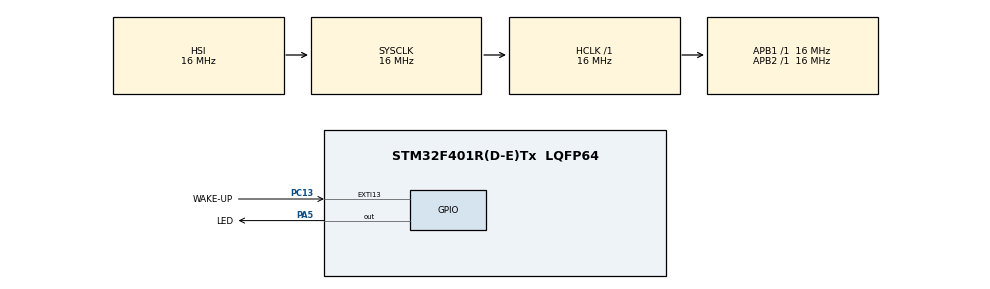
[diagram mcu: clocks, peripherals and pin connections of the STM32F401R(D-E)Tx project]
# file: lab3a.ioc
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Mcu.Family=STM32F4
Mcu.Name=STM32F401R(D-E)Tx
Mcu.Package=LQFP64
NVIC.EXTI15_10_IRQn=true\:0\:0\:false\:false\:true\:true\:true\:true
NVIC.PriorityGroup=NVIC_PRIORITYGROUP_4
PA5.GPIO_Label=LED
PA5.Signal=GPIO_Output
PC13-ANTI_TAMP.GPIO_Label=WAKE-UP
PC13-ANTI_TAMP.GPIO_ModeDefaultEXTI=GPIO_MODE_IT_FALLING
PC13-ANTI_TAMP.Signal=GPXTI13
ProjectManager.HeapSize=0x200
ProjectManager.StackSize=0x400
ProjectManager.TargetToolchain=STM32CubeIDE
RCC.AHBFreq_Value=16000000
RCC.APB1Freq_Value=16000000
RCC.APB2Freq_Value=16000000
RCC.CortexFreq_Value=16000000
RCC.HSE_VALUE=25000000
RCC.HSI_VALUE=16000000
RCC.LSE_VALUE=32768
RCC.SYSCLKFreq_VALUE=16000000
RCC.VCOOutputFreq_Value=192000000
board=custom

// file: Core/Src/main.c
/* USER CODE BEGIN Header */
/**
  ******************************************************************************
  * @file           : main.c
  * @brief          : Main program body
  ******************************************************************************
  * @attention
  *
  * Copyright (c) 2026 STMicroelectronics.
  * All rights reserved.
  *
  * This software is licensed under terms that can be found in the LICENSE file
  * in the root directory of this software component.
  * If no LICENSE file comes with this software, it is provided AS-IS.
  *
  ******************************************************************************
  */
/* USER CODE END Header */
#include "main.h"

/* ------------------------- Globals ------------------------- */
volatile uint32_t g_wakeCount = 0;
volatile uint8_t  g_doBlink  = 0;

void SystemClock_Config(void);
static void MX_GPIO_Init(void);
static void BlinkTimes(uint32_t n);

int main(void)
{

  /* MCU Configuration--------------------------------------------------------*/

  /* Reset of all peripherals, Initializes the Flash interface and the Systick. */
  HAL_Init();

  /* Configure the system clock */
  SystemClock_Config();

  /* Initialize all configured peripherals */
  MX_GPIO_Init();
  /* USER CODE BEGIN 2 */

  BlinkTimes(1);
  /* USER CODE END 2 */

  /* Infinite loop */
  while (1)
  {

	    /* If we woke due to button, perform visible action and show counter */
	    if (g_doBlink)
	    {
	      g_doBlink = 0;

	      /* Blink g_wakeCount times so you can see the counter is preserved */
	      BlinkTimes(g_wakeCount);
	    }

	    /* --- Prepare to enter STOP --- */

	    /* Clear any pending EXTI flag (prevents immediate wake / "won't sleep") */
	    __HAL_GPIO_EXTI_CLEAR_IT(GPIO_PIN_13);

	    /* (Optional) Clear WakeUp flag (safe even if not set) */
	    __HAL_PWR_CLEAR_FLAG(PWR_FLAG_WU);
	    /* Enter STOP mode (low-power regulator ON), wake on EXTI interrupt */
	    HAL_PWR_EnterSTOPMode(PWR_LOWPOWERREGULATOR_ON, PWR_STOPENTRY_WFI);

	    /* --- We resume here after wake from STOP --- */

  }
}

/* ------------------------- Blink Helper ------------------------- */
static void BlinkTimes(uint32_t n)
{
  for (uint32_t i = 0; i < n; i++)
  {
    HAL_GPIO_WritePin(GPIOA, GPIO_PIN_5, GPIO_PIN_SET);
    HAL_Delay(120);
    HAL_GPIO_WritePin(GPIOA, GPIO_PIN_5, GPIO_PIN_RESET);
    HAL_Delay(120);
  }

  /* small gap after the sequence */
  HAL_Delay(250);
}

/* ---------------------- EXTI Callback ---------------------- */
void HAL_GPIO_EXTI_Callback(uint16_t GPIO_Pin)
{
  if (GPIO_Pin == GPIO_PIN_13) /* USER button B1: PC13 */
  {
    /* Simple debounce: ignore bounces within ~150ms */
    static uint32_t lastTick = 0;
    uint32_t now = HAL_GetTick();
    if ((now - lastTick) < 150) return;
    lastTick = now;

    g_wakeCount++;
    g_doBlink = 1;
  }
}

void SystemClock_Config(void)
{
  RCC_OscInitTypeDef RCC_OscInitStruct = {0};
  RCC_ClkInitTypeDef RCC_ClkInitStruct = {0};

  /** Configure the main internal regulator output voltage
  */
  __HAL_RCC_PWR_CLK_ENABLE();
  __HAL_PWR_VOLTAGESCALING_CONFIG(PWR_REGULATOR_VOLTAGE_SCALE2);

  /** Initializes the RCC Oscillators according to the specified parameters
  * in the RCC_OscInitTypeDef structure.
  */
  RCC_OscInitStruct.OscillatorType = RCC_OSCILLATORTYPE_HSI;
  RCC_OscInitStruct.HSIState = RCC_HSI_ON;
  RCC_OscInitStruct.HSICalibrationValue = RCC_HSICALIBRATION_DEFAULT;
  RCC_OscInitStruct.PLL.PLLState = RCC_PLL_NONE;
  if (HAL_RCC_OscConfig(&RCC_OscInitStruct) != HAL_OK)
  {
    Error_Handler();
  }

  /** Initializes the CPU, AHB and APB buses clocks
  */
  RCC_ClkInitStruct.ClockType = RCC_CLOCKTYPE_HCLK|RCC_CLOCKTYPE_SYSCLK
                              |RCC_CLOCKTYPE_PCLK1|RCC_CLOCKTYPE_PCLK2;
  RCC_ClkInitStruct.SYSCLKSource = RCC_SYSCLKSOURCE_HSI;
  RCC_ClkInitStruct.AHBCLKDivider = RCC_SYSCLK_DIV1;
  RCC_ClkInitStruct.APB1CLKDivider = RCC_HCLK_DIV1;
  RCC_ClkInitStruct.APB2CLKDivider = RCC_HCLK_DIV1;

  if (HAL_RCC_ClockConfig(&RCC_ClkInitStruct, FLASH_LATENCY_0) != HAL_OK)
  {
    Error_Handler();
  }
}

static void MX_GPIO_Init(void)
{
  GPIO_InitTypeDef GPIO_InitStruct = {0};

  /* GPIO Ports Clock Enable */
  __HAL_RCC_GPIOC_CLK_ENABLE();
  __HAL_RCC_GPIOA_CLK_ENABLE();

  /*Configure GPIO pin Output Level */
  HAL_GPIO_WritePin(LED_GPIO_Port, LED_Pin, GPIO_PIN_RESET);

  /*Configure GPIO pin : WAKE_UP_Pin */
  GPIO_InitStruct.Pin = WAKE_UP_Pin;
  GPIO_InitStruct.Mode = GPIO_MODE_IT_FALLING;
  GPIO_InitStruct.Pull = GPIO_NOPULL;
  HAL_GPIO_Init(WAKE_UP_GPIO_Port, &GPIO_InitStruct);

  /*Configure GPIO pin : LED_Pin */
  GPIO_InitStruct.Pin = LED_Pin;
  GPIO_InitStruct.Mode = GPIO_MODE_OUTPUT_PP;
  GPIO_InitStruct.Pull = GPIO_NOPULL;
  GPIO_InitStruct.Speed = GPIO_SPEED_FREQ_LOW;
  HAL_GPIO_Init(LED_GPIO_Port, &GPIO_InitStruct);

  /* EXTI interrupt init*/
  HAL_NVIC_SetPriority(EXTI15_10_IRQn, 0, 0);
  HAL_NVIC_EnableIRQ(EXTI15_10_IRQn);

}

void Error_Handler(void)
{
  __disable_irq();
  while (1)
  {
  }
}
